# nrf54lc10a_application register map
Vendor: Nordic Semiconductor; Series: nrf54l; File version: 1
CPU: CM33 r0p4, little endian, MPU, FPU, 3 interrupt priority bits, 270 interrupts, 4 SAU regions
Registers are 32-bit, read-write, reset 0x0 unless marked. A register's access mark holds for its fields unless they carry their own. Offsets are from the block's base; [hi:lo] are bit positions; lines under a group give offsets from that group; {n}, {i} and the like mark numbered series; 'fields as' and 'values as' point back to an identical list.

## GLOBAL_RADIO_NS — 2.4 GHz radio 0
Base 0x4008A000
Same registers: GLOBAL_RADIO_S 0x5008A000
0x00 TASKS_TXEN wo — Enable RADIO in TX mode
  [0] TASKS_TXEN
    1=Trigger task
0x04 TASKS_RXEN wo — Enable RADIO in RX mode
  [0] TASKS_RXEN
    1=Trigger task
0x08 TASKS_START wo — Start RADIO
  [0] TASKS_START
    1=Trigger task
0x0C TASKS_STOP wo — Stop RADIO
  [0] TASKS_STOP
    1=Trigger task
0x10 TASKS_DISABLE wo — Disable RADIO
  [0] TASKS_DISABLE
    1=Trigger task
0x14 TASKS_RSSISTART wo — Start the RSSI and take one single sample of the receive signal strength
  [0] TASKS_RSSISTART
    1=Trigger task
0x18 TASKS_BCSTART wo — Start the bit counter
  [0] TASKS_BCSTART
    1=Trigger task
0x1C TASKS_BCSTOP wo — Stop the bit counter
  [0] TASKS_BCSTOP
    1=Trigger task
0x20 TASKS_EDSTART wo — Start the energy detect measurement used in IEEE 802.15.4 mode
  [0] TASKS_EDSTART
    1=Trigger task
0x24 TASKS_EDSTOP wo — Stop the energy detect measurement
  [0] TASKS_EDSTOP
    1=Trigger task
0x28 TASKS_CCASTART wo — Start the clear channel assessment used in IEEE 802.15.4 mode
  [0] TASKS_CCASTART
    1=Trigger task
0x2C TASKS_CCASTOP wo — Stop the clear channel assessment
  [0] TASKS_CCASTOP
    1=Trigger task
0x38 TASKS_AUXDATADMASTART wo — Start DMA transaction of acquisition
  [0] TASKS_AUXDATADMASTART
    1=Trigger task
0x3C TASKS_AUXDATADMASTOP wo — Stop ongoing DMA transaction of acquisition
  [0] TASKS_AUXDATADMASTOP
    1=Trigger task
0x6C TASKS_PLLEN wo — Enable RADIO in PLL mode (standby for either TX or RX)
  [0] TASKS_PLLEN
    1=Trigger task
0xA0 TASKS_CSTONESSTART wo — Start tone processing for channel sounding
  [0] TASKS_CSTONESSTART
    1=Trigger task
0xA4 TASKS_SOFTRESET wo — Reset all public registers, but with these exceptions: DMA registers and EVENT/INTEN/SUBSCRIBE/PUBLISH registers. Only to be used in DISABLED state.
  [0] TASKS_SOFTRESET
    1=Trigger task
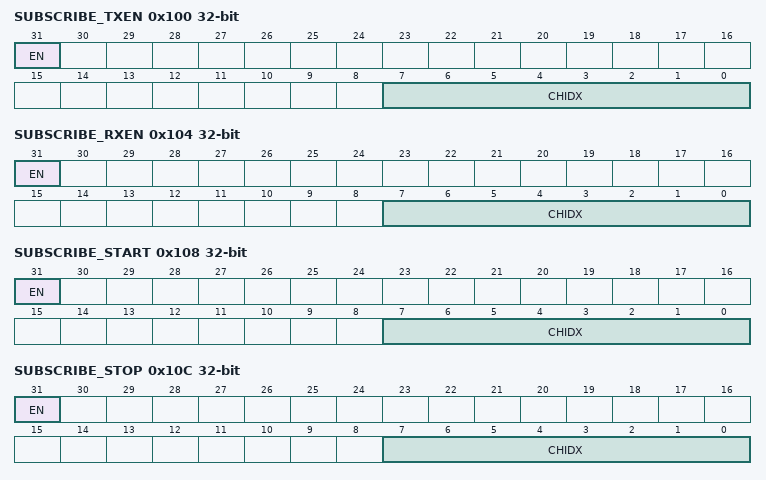
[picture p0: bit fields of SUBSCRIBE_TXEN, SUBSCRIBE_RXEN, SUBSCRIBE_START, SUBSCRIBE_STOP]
0x100 SUBSCRIBE_TXEN — Subscribe configuration for task TXEN
  [31] EN
    0=Disabled (Disable subscription); 1=Enabled (Enable subscription)
  [7:0] CHIDX — DPPI channel that task TXEN will subscribe to
0x104 SUBSCRIBE_RXEN — Subscribe configuration for task RXEN
  [31] EN
    values as SUBSCRIBE_TXEN.EN
  [7:0] CHIDX — DPPI channel that task RXEN will subscribe to
0x108 SUBSCRIBE_START — Subscribe configuration for task START
  [31] EN
    values as SUBSCRIBE_TXEN.EN
  [7:0] CHIDX — DPPI channel that task START will subscribe to
0x10C SUBSCRIBE_STOP — Subscribe configuration for task STOP
  [31] EN
    values as SUBSCRIBE_TXEN.EN
  [7:0] CHIDX — DPPI channel that task STOP will subscribe to
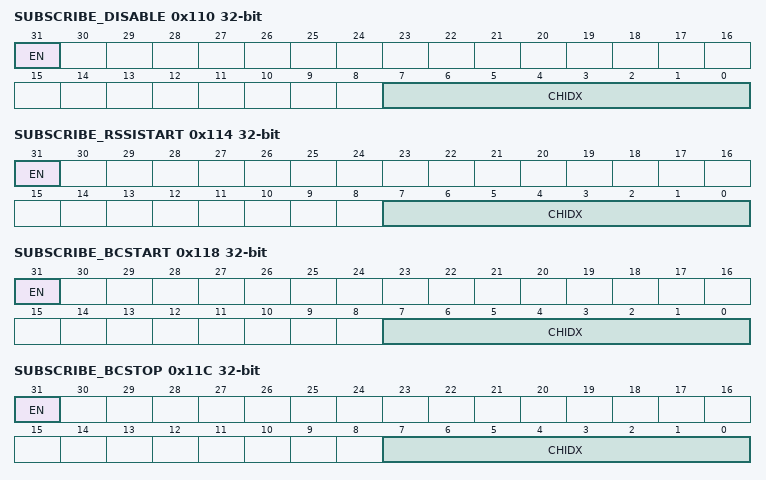
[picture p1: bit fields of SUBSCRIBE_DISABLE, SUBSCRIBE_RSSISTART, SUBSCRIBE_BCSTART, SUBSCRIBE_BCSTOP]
0x110 SUBSCRIBE_DISABLE — Subscribe configuration for task DISABLE
  [31] EN
    values as SUBSCRIBE_TXEN.EN
  [7:0] CHIDX — DPPI channel that task DISABLE will subscribe to
0x114 SUBSCRIBE_RSSISTART — Subscribe configuration for task RSSISTART
  [31] EN
    values as SUBSCRIBE_TXEN.EN
  [7:0] CHIDX — DPPI channel that task RSSISTART will subscribe to
0x118 SUBSCRIBE_BCSTART — Subscribe configuration for task BCSTART
  [31] EN
    values as SUBSCRIBE_TXEN.EN
  [7:0] CHIDX — DPPI channel that task BCSTART will subscribe to
0x11C SUBSCRIBE_BCSTOP — Subscribe configuration for task BCSTOP
  [31] EN
    values as SUBSCRIBE_TXEN.EN
  [7:0] CHIDX — DPPI channel that task BCSTOP will subscribe to
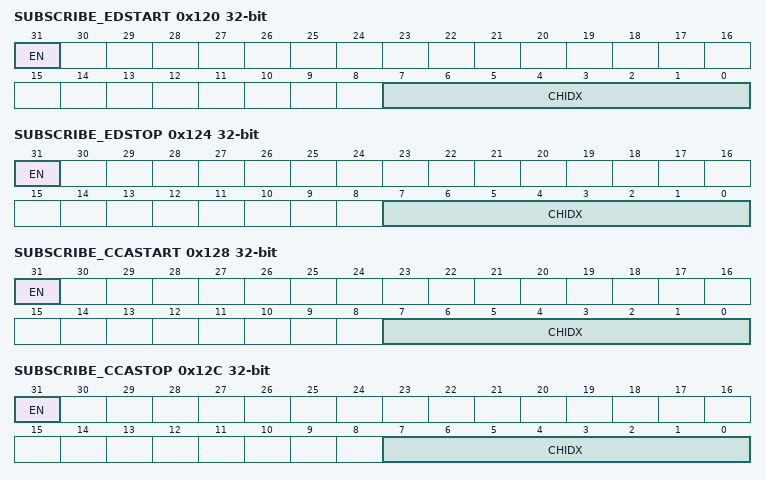
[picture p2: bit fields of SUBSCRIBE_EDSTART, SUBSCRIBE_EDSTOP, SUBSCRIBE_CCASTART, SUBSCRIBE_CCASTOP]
0x120 SUBSCRIBE_EDSTART — Subscribe configuration for task EDSTART
  [31] EN
    values as SUBSCRIBE_TXEN.EN
  [7:0] CHIDX — DPPI channel that task EDSTART will subscribe to
0x124 SUBSCRIBE_EDSTOP — Subscribe configuration for task EDSTOP
  [31] EN
    values as SUBSCRIBE_TXEN.EN
  [7:0] CHIDX — DPPI channel that task EDSTOP will subscribe to
0x128 SUBSCRIBE_CCASTART — Subscribe configuration for task CCASTART
  [31] EN
    values as SUBSCRIBE_TXEN.EN
  [7:0] CHIDX — DPPI channel that task CCASTART will subscribe to
0x12C SUBSCRIBE_CCASTOP — Subscribe configuration for task CCASTOP
  [31] EN
    values as SUBSCRIBE_TXEN.EN
  [7:0] CHIDX — DPPI channel that task CCASTOP will subscribe to
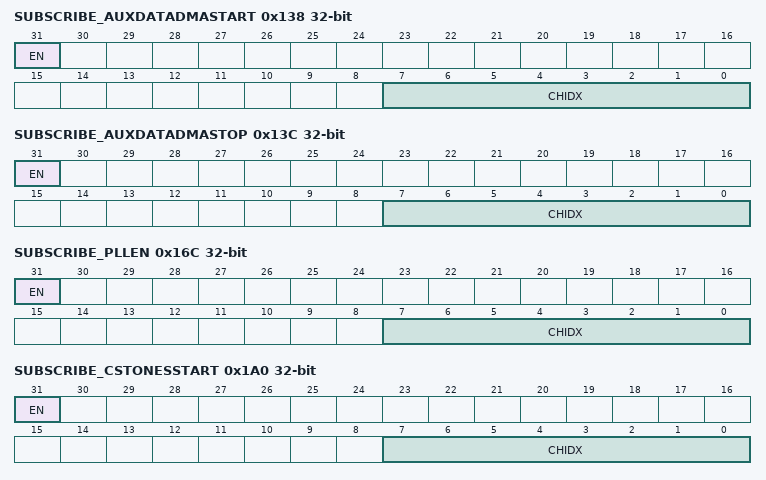
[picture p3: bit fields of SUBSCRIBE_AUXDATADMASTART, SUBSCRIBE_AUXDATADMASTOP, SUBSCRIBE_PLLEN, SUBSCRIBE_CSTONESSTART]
0x138 SUBSCRIBE_AUXDATADMASTART — Subscribe configuration for task AUXDATADMASTART
  [31] EN
    values as SUBSCRIBE_TXEN.EN
  [7:0] CHIDX — DPPI channel that task AUXDATADMASTART will subscribe to
0x13C SUBSCRIBE_AUXDATADMASTOP — Subscribe configuration for task AUXDATADMASTOP
  [31] EN
    values as SUBSCRIBE_TXEN.EN
  [7:0] CHIDX — DPPI channel that task AUXDATADMASTOP will subscribe to
0x16C SUBSCRIBE_PLLEN — Subscribe configuration for task PLLEN
  [31] EN
    values as SUBSCRIBE_TXEN.EN
  [7:0] CHIDX — DPPI channel that task PLLEN will subscribe to
0x1A0 SUBSCRIBE_CSTONESSTART — Subscribe configuration for task CSTONESSTART
  [31] EN
    values as SUBSCRIBE_TXEN.EN
  [7:0] CHIDX — DPPI channel that task CSTONESSTART will subscribe to
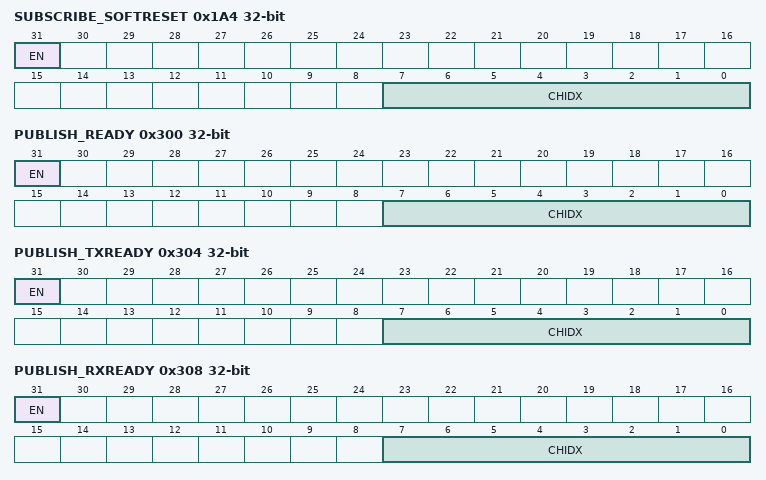
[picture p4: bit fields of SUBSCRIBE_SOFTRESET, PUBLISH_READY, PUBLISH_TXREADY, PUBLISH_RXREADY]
0x1A4 SUBSCRIBE_SOFTRESET — Subscribe configuration for task SOFTRESET
  [31] EN
    values as SUBSCRIBE_TXEN.EN
  [7:0] CHIDX — DPPI channel that task SOFTRESET will subscribe to
0x200 EVENTS_READY — RADIO has ramped up and is ready to be started
  [0] EVENTS_READY
    0=NotGenerated (Event not generated); 1=Generated (Event generated)
0x204 EVENTS_TXREADY — RADIO has ramped up and is ready to be started TX path
  [0] EVENTS_TXREADY
    values as EVENTS_READY.EVENTS_READY
0x208 EVENTS_RXREADY — RADIO has ramped up and is ready to be started RX path
  [0] EVENTS_RXREADY
    values as EVENTS_READY.EVENTS_READY
0x20C EVENTS_ADDRESS — Address sent or received
  [0] EVENTS_ADDRESS
    values as EVENTS_READY.EVENTS_READY
0x210 EVENTS_FRAMESTART — IEEE 802.15.4 length field received
  [0] EVENTS_FRAMESTART
    values as EVENTS_READY.EVENTS_READY
0x214 EVENTS_PAYLOAD — Packet payload sent or received
  [0] EVENTS_PAYLOAD
    values as EVENTS_READY.EVENTS_READY
0x218 EVENTS_END — Memory access for packet data has been completed
  [0] EVENTS_END
    values as EVENTS_READY.EVENTS_READY
0x21C EVENTS_PHYEND — The last bit is sent on air or last bit is received
  [0] EVENTS_PHYEND
    values as EVENTS_READY.EVENTS_READY
0x220 EVENTS_DISABLED — RADIO has been disabled
  [0] EVENTS_DISABLED
    values as EVENTS_READY.EVENTS_READY
0x224 EVENTS_DEVMATCH — A device address match occurred on the last received packet
  [0] EVENTS_DEVMATCH
    values as EVENTS_READY.EVENTS_READY
0x228 EVENTS_DEVMISS — No device address match occurred on the last received packet
  [0] EVENTS_DEVMISS
    values as EVENTS_READY.EVENTS_READY
0x22C EVENTS_CRCOK — Packet received with CRC ok
  [0] EVENTS_CRCOK
    values as EVENTS_READY.EVENTS_READY
0x230 EVENTS_CRCERROR — Packet received with CRC error
  [0] EVENTS_CRCERROR
    values as EVENTS_READY.EVENTS_READY
0x238 EVENTS_BCMATCH — Bit counter reached bit count value
  [0] EVENTS_BCMATCH
    values as EVENTS_READY.EVENTS_READY
0x23C EVENTS_EDEND — Sampling of energy detection complete (a new ED sample is ready for readout from the RADIO.EDSAMPLE register)
  [0] EVENTS_EDEND
    values as EVENTS_READY.EVENTS_READY
0x240 EVENTS_EDSTOPPED — The sampling of energy detection has stopped
  [0] EVENTS_EDSTOPPED
    values as EVENTS_READY.EVENTS_READY
0x244 EVENTS_CCAIDLE — Wireless medium in idle - clear to send
  [0] EVENTS_CCAIDLE
    values as EVENTS_READY.EVENTS_READY
0x248 EVENTS_CCABUSY — Wireless medium busy - do not send
  [0] EVENTS_CCABUSY
    values as EVENTS_READY.EVENTS_READY
0x24C EVENTS_CCASTOPPED — The CCA has stopped
  [0] EVENTS_CCASTOPPED
    values as EVENTS_READY.EVENTS_READY
0x250 EVENTS_RATEBOOST — Ble_LR CI field received, receive mode is changed from Ble_LR125Kbit to Ble_LR500Kbit
  [0] EVENTS_RATEBOOST
    values as EVENTS_READY.EVENTS_READY
0x254 EVENTS_MHRMATCH — MAC header match found
  [0] EVENTS_MHRMATCH
    values as EVENTS_READY.EVENTS_READY
0x258 EVENTS_SYNC — Initial sync detected
  [0] EVENTS_SYNC
    values as EVENTS_READY.EVENTS_READY
0x25C EVENTS_CTEPRESENT — CTEInfo byte is received
  [0] EVENTS_CTEPRESENT
    values as EVENTS_READY.EVENTS_READY
0x2B0 EVENTS_PLLREADY — PLL has settled and RADIO is ready to be enabled in either TX or RX mode
  [0] EVENTS_PLLREADY
    values as EVENTS_READY.EVENTS_READY
0x2BC EVENTS_RXADDRESS — Address received
  [0] EVENTS_RXADDRESS
    values as EVENTS_READY.EVENTS_READY
0x2C0 EVENTS_AUXDATADMAEND — AUXDATA DMA end
  [0] EVENTS_AUXDATADMAEND
    values as EVENTS_READY.EVENTS_READY
0x2C8 EVENTS_CSTONESEND — The channel sounding tone processing is complete
  [0] EVENTS_CSTONESEND
    values as EVENTS_READY.EVENTS_READY
0x300 PUBLISH_READY — Publish configuration for event READY
  [31] EN
    0=Disabled (Disable publishing); 1=Enabled (Enable publishing)
  [7:0] CHIDX — DPPI channel that event READY will publish to
0x304 PUBLISH_TXREADY — Publish configuration for event TXREADY
  [31] EN
    values as PUBLISH_READY.EN
  [7:0] CHIDX — DPPI channel that event TXREADY will publish to
0x308 PUBLISH_RXREADY — Publish configuration for event RXREADY
  [31] EN
    values as PUBLISH_READY.EN
  [7:0] CHIDX — DPPI channel that event RXREADY will publish to
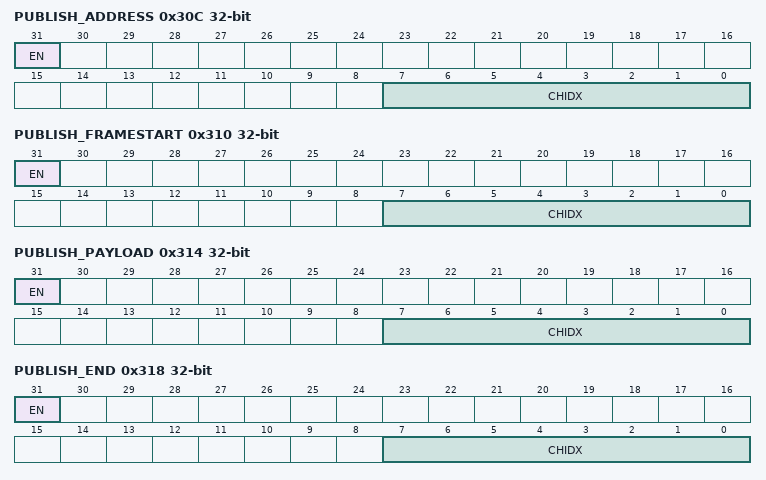
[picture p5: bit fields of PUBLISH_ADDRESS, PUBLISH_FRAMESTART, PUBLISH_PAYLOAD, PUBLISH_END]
0x30C PUBLISH_ADDRESS — Publish configuration for event ADDRESS
  [31] EN
    values as PUBLISH_READY.EN
  [7:0] CHIDX — DPPI channel that event ADDRESS will publish to
0x310 PUBLISH_FRAMESTART — Publish configuration for event FRAMESTART
  [31] EN
    values as PUBLISH_READY.EN
  [7:0] CHIDX — DPPI channel that event FRAMESTART will publish to
0x314 PUBLISH_PAYLOAD — Publish configuration for event PAYLOAD
  [31] EN
    values as PUBLISH_READY.EN
  [7:0] CHIDX — DPPI channel that event PAYLOAD will publish to
0x318 PUBLISH_END — Publish configuration for event END
  [31] EN
    values as PUBLISH_READY.EN
  [7:0] CHIDX — DPPI channel that event END will publish to
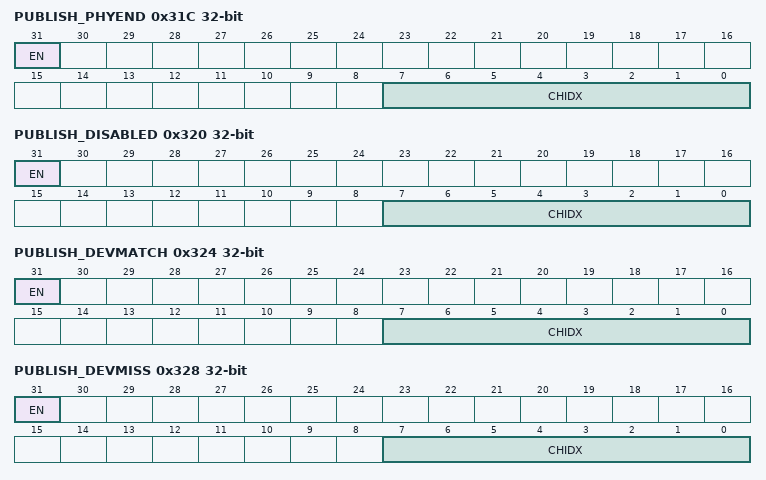
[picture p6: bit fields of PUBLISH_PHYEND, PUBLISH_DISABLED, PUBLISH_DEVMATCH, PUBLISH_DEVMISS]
0x31C PUBLISH_PHYEND — Publish configuration for event PHYEND
  [31] EN
    values as PUBLISH_READY.EN
  [7:0] CHIDX — DPPI channel that event PHYEND will publish to
0x320 PUBLISH_DISABLED — Publish configuration for event DISABLED
  [31] EN
    values as PUBLISH_READY.EN
  [7:0] CHIDX — DPPI channel that event DISABLED will publish to
0x324 PUBLISH_DEVMATCH — Publish configuration for event DEVMATCH
  [31] EN
    values as PUBLISH_READY.EN
  [7:0] CHIDX — DPPI channel that event DEVMATCH will publish to
0x328 PUBLISH_DEVMISS — Publish configuration for event DEVMISS
  [31] EN
    values as PUBLISH_READY.EN
  [7:0] CHIDX — DPPI channel that event DEVMISS will publish to
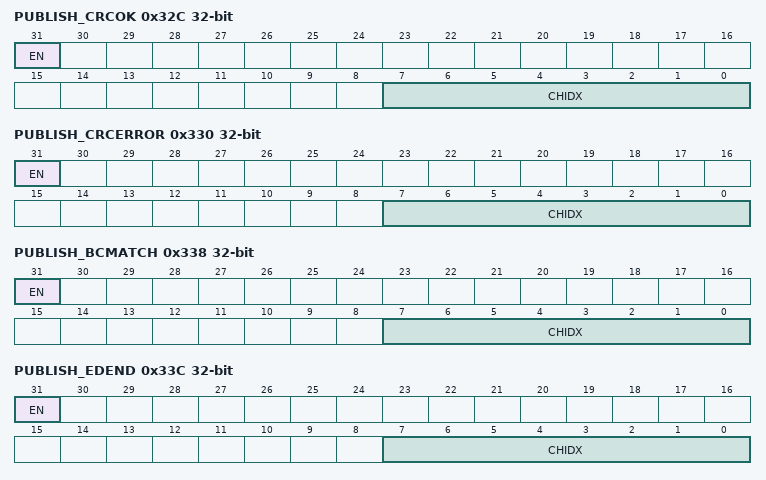
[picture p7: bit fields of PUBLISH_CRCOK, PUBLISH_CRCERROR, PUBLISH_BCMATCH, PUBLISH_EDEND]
0x32C PUBLISH_CRCOK — Publish configuration for event CRCOK
  [31] EN
    values as PUBLISH_READY.EN
  [7:0] CHIDX — DPPI channel that event CRCOK will publish to
0x330 PUBLISH_CRCERROR — Publish configuration for event CRCERROR
  [31] EN
    values as PUBLISH_READY.EN
  [7:0] CHIDX — DPPI channel that event CRCERROR will publish to
0x338 PUBLISH_BCMATCH — Publish configuration for event BCMATCH
  [31] EN
    values as PUBLISH_READY.EN
  [7:0] CHIDX — DPPI channel that event BCMATCH will publish to
0x33C PUBLISH_EDEND — Publish configuration for event EDEND
  [31] EN
    values as PUBLISH_READY.EN
  [7:0] CHIDX — DPPI channel that event EDEND will publish to
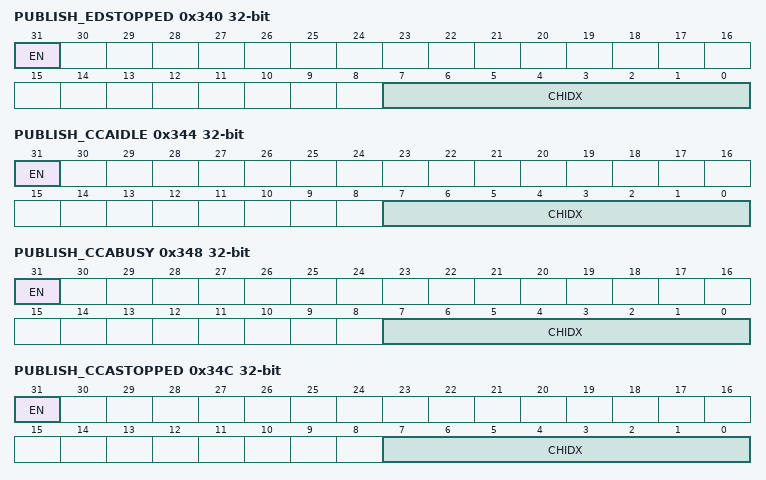
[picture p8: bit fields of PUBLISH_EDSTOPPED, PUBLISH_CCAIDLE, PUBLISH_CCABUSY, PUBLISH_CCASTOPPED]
0x340 PUBLISH_EDSTOPPED — Publish configuration for event EDSTOPPED
  [31] EN
    values as PUBLISH_READY.EN
  [7:0] CHIDX — DPPI channel that event EDSTOPPED will publish to
0x344 PUBLISH_CCAIDLE — Publish configuration for event CCAIDLE
  [31] EN
    values as PUBLISH_READY.EN
  [7:0] CHIDX — DPPI channel that event CCAIDLE will publish to
0x348 PUBLISH_CCABUSY — Publish configuration for event CCABUSY
  [31] EN
    values as PUBLISH_READY.EN
  [7:0] CHIDX — DPPI channel that event CCABUSY will publish to
0x34C PUBLISH_CCASTOPPED — Publish configuration for event CCASTOPPED
  [31] EN
    values as PUBLISH_READY.EN
  [7:0] CHIDX — DPPI channel that event CCASTOPPED will publish to
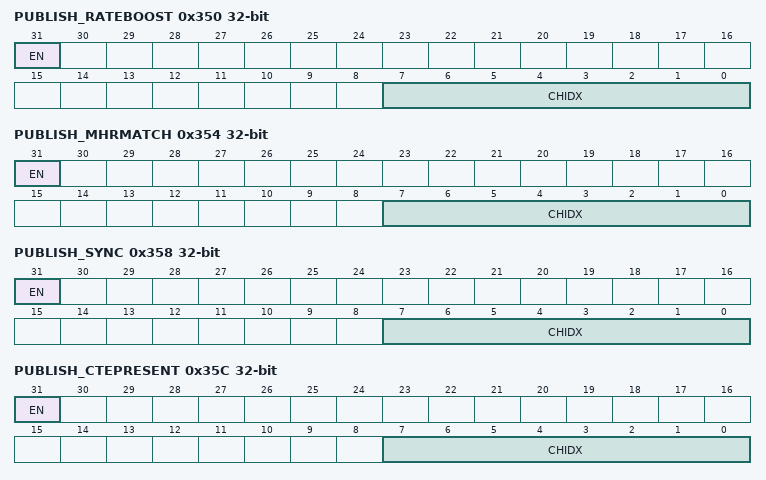
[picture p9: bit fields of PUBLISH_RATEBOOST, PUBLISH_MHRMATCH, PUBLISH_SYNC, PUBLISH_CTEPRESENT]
0x350 PUBLISH_RATEBOOST — Publish configuration for event RATEBOOST
  [31] EN
    values as PUBLISH_READY.EN
  [7:0] CHIDX — DPPI channel that event RATEBOOST will publish to
0x354 PUBLISH_MHRMATCH — Publish configuration for event MHRMATCH
  [31] EN
    values as PUBLISH_READY.EN
  [7:0] CHIDX — DPPI channel that event MHRMATCH will publish to
0x358 PUBLISH_SYNC — Publish configuration for event SYNC
  [31] EN
    values as PUBLISH_READY.EN
  [7:0] CHIDX — DPPI channel that event SYNC will publish to
0x35C PUBLISH_CTEPRESENT — Publish configuration for event CTEPRESENT
  [31] EN
    values as PUBLISH_READY.EN
  [7:0] CHIDX — DPPI channel that event CTEPRESENT will publish to
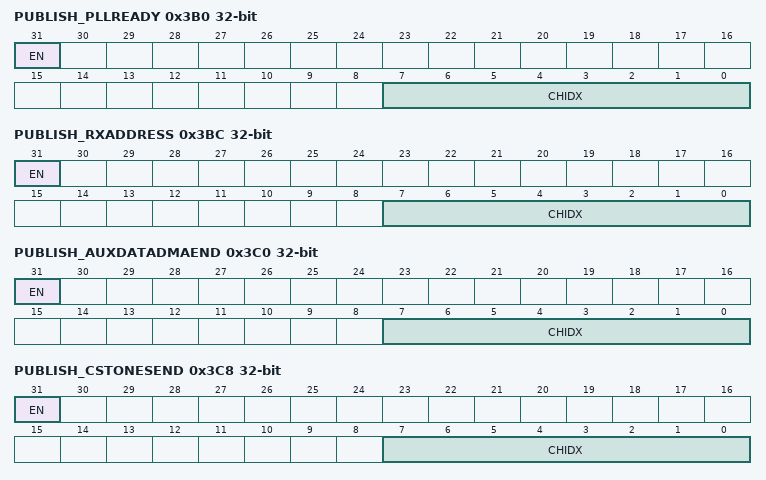
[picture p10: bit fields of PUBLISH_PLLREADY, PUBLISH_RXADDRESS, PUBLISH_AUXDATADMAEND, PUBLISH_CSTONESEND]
0x3B0 PUBLISH_PLLREADY — Publish configuration for event PLLREADY
  [31] EN
    values as PUBLISH_READY.EN
  [7:0] CHIDX — DPPI channel that event PLLREADY will publish to
0x3BC PUBLISH_RXADDRESS — Publish configuration for event RXADDRESS
  [31] EN
    values as PUBLISH_READY.EN
  [7:0] CHIDX — DPPI channel that event RXADDRESS will publish to
0x3C0 PUBLISH_AUXDATADMAEND — Publish configuration for event AUXDATADMAEND
  [31] EN
    values as PUBLISH_READY.EN
  [7:0] CHIDX — DPPI channel that event AUXDATADMAEND will publish to
0x3C8 PUBLISH_CSTONESEND — Publish configuration for event CSTONESEND
  [31] EN
    values as PUBLISH_READY.EN
  [7:0] CHIDX — DPPI channel that event CSTONESEND will publish to
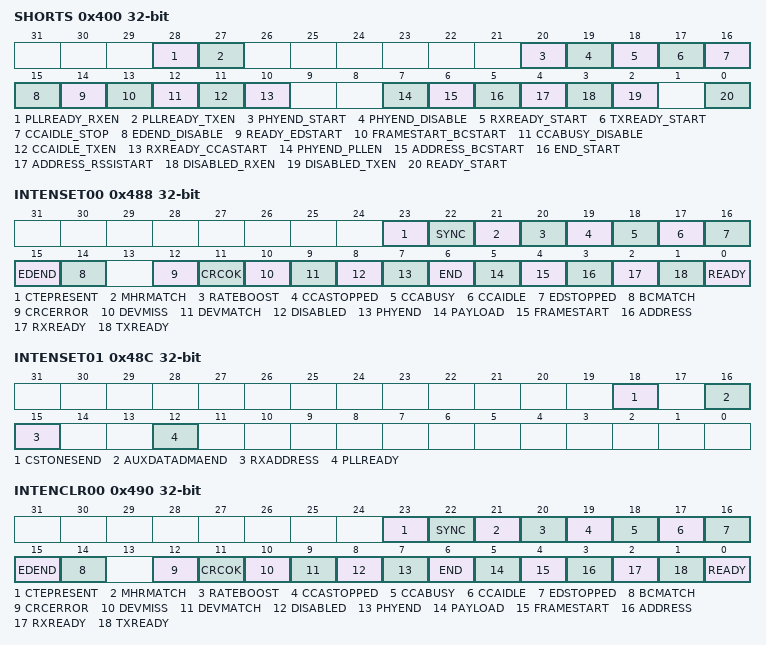
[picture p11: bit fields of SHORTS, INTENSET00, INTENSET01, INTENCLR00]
0x400 SHORTS — Shortcuts between local events and tasks
  [all] fields
    0=Disabled (Disable shortcut); 1=Enabled (Enable shortcut)
  [28] PLLREADY_RXEN — Shortcut between event PLLREADY and task RXEN
  [27] PLLREADY_TXEN — Shortcut between event PLLREADY and task TXEN
  [20] PHYEND_START — Shortcut between event PHYEND and task START
  [19] PHYEND_DISABLE — Shortcut between event PHYEND and task DISABLE
  [18] RXREADY_START — Shortcut between event RXREADY and task START
  [17] TXREADY_START — Shortcut between event TXREADY and task START
  [16] CCAIDLE_STOP — Shortcut between event CCAIDLE and task STOP
  [15] EDEND_DISABLE — Shortcut between event EDEND and task DISABLE
  [14] READY_EDSTART — Shortcut between event READY and task EDSTART
  [13] FRAMESTART_BCSTART — Shortcut between event FRAMESTART and task BCSTART
  [12] CCABUSY_DISABLE — Shortcut between event CCABUSY and task DISABLE
  [11] CCAIDLE_TXEN — Shortcut between event CCAIDLE and task TXEN
  [10] RXREADY_CCASTART — Shortcut between event RXREADY and task CCASTART
  [7] PHYEND_PLLEN — Shortcut between event PHYEND and task PLLEN
  [6] ADDRESS_BCSTART — Shortcut between event ADDRESS and task BCSTART
  [5] END_START — Shortcut between event END and task START
  [4] ADDRESS_RSSISTART — Shortcut between event ADDRESS and task RSSISTART
  [3] DISABLED_RXEN — Shortcut between event DISABLED and task RXEN
  [2] DISABLED_TXEN — Shortcut between event DISABLED and task TXEN
  [0] READY_START — Shortcut between event READY and task START
0x488 INTENSET00 — Enable interrupt
  [all] fields
    on read: 0=Disabled (Read: Disabled); 1=Enabled (Read: Enabled) | on write: 1=Set (Enable)
  [23] CTEPRESENT write-1-sets — Write '1' to enable interrupt for event CTEPRESENT
  [22] SYNC write-1-sets — Write '1' to enable interrupt for event SYNC
  [21] MHRMATCH write-1-sets — Write '1' to enable interrupt for event MHRMATCH
  [20] RATEBOOST write-1-sets — Write '1' to enable interrupt for event RATEBOOST
  [19] CCASTOPPED write-1-sets — Write '1' to enable interrupt for event CCASTOPPED
  [18] CCABUSY write-1-sets — Write '1' to enable interrupt for event CCABUSY
  [17] CCAIDLE write-1-sets — Write '1' to enable interrupt for event CCAIDLE
  [16] EDSTOPPED write-1-sets — Write '1' to enable interrupt for event EDSTOPPED
  [15] EDEND write-1-sets — Write '1' to enable interrupt for event EDEND
  [14] BCMATCH write-1-sets — Write '1' to enable interrupt for event BCMATCH
  [12] CRCERROR write-1-sets — Write '1' to enable interrupt for event CRCERROR
  [11] CRCOK write-1-sets — Write '1' to enable interrupt for event CRCOK
  [10] DEVMISS write-1-sets — Write '1' to enable interrupt for event DEVMISS
  [9] DEVMATCH write-1-sets — Write '1' to enable interrupt for event DEVMATCH
  [8] DISABLED write-1-sets — Write '1' to enable interrupt for event DISABLED
  [7] PHYEND write-1-sets — Write '1' to enable interrupt for event PHYEND
  [6] END write-1-sets — Write '1' to enable interrupt for event END
  [5] PAYLOAD write-1-sets — Write '1' to enable interrupt for event PAYLOAD
  [4] FRAMESTART write-1-sets — Write '1' to enable interrupt for event FRAMESTART
  [3] ADDRESS write-1-sets — Write '1' to enable interrupt for event ADDRESS
  [2] RXREADY write-1-sets — Write '1' to enable interrupt for event RXREADY
  [1] TXREADY write-1-sets — Write '1' to enable interrupt for event TXREADY
  [0] READY write-1-sets — Write '1' to enable interrupt for event READY
0x48C INTENSET01 — Enable interrupt
  [all] fields
    values as the fields of INTENSET00
  [18] CSTONESEND write-1-sets — Write '1' to enable interrupt for event CSTONESEND
  [16] AUXDATADMAEND write-1-sets — Write '1' to enable interrupt for event AUXDATADMAEND
  [15] RXADDRESS write-1-sets — Write '1' to enable interrupt for event RXADDRESS
  [12] PLLREADY write-1-sets — Write '1' to enable interrupt for event PLLREADY
0x490 INTENCLR00 — Disable interrupt
  [all] fields
    on read: 0=Disabled (Read: Disabled); 1=Enabled (Read: Enabled) | on write: 1=Clear (Disable)
  [23] CTEPRESENT write-1-clears — Write '1' to disable interrupt for event CTEPRESENT
  [22] SYNC write-1-clears — Write '1' to disable interrupt for event SYNC
  [21] MHRMATCH write-1-clears — Write '1' to disable interrupt for event MHRMATCH
  [20] RATEBOOST write-1-clears — Write '1' to disable interrupt for event RATEBOOST
  [19] CCASTOPPED write-1-clears — Write '1' to disable interrupt for event CCASTOPPED
  [18] CCABUSY write-1-clears — Write '1' to disable interrupt for event CCABUSY
  [17] CCAIDLE write-1-clears — Write '1' to disable interrupt for event CCAIDLE
  [16] EDSTOPPED write-1-clears — Write '1' to disable interrupt for event EDSTOPPED
  [15] EDEND write-1-clears — Write '1' to disable interrupt for event EDEND
  [14] BCMATCH write-1-clears — Write '1' to disable interrupt for event BCMATCH
  [12] CRCERROR write-1-clears — Write '1' to disable interrupt for event CRCERROR
  [11] CRCOK write-1-clears — Write '1' to disable interrupt for event CRCOK
  [10] DEVMISS write-1-clears — Write '1' to disable interrupt for event DEVMISS
  [9] DEVMATCH write-1-clears — Write '1' to disable interrupt for event DEVMATCH
  [8] DISABLED write-1-clears — Write '1' to disable interrupt for event DISABLED
  [7] PHYEND write-1-clears — Write '1' to disable interrupt for event PHYEND
  [6] END write-1-clears — Write '1' to disable interrupt for event END
  [5] PAYLOAD write-1-clears — Write '1' to disable interrupt for event PAYLOAD
  [4] FRAMESTART write-1-clears — Write '1' to disable interrupt for event FRAMESTART
  [3] ADDRESS write-1-clears — Write '1' to disable interrupt for event ADDRESS
  [2] RXREADY write-1-clears — Write '1' to disable interrupt for event RXREADY
  [1] TXREADY write-1-clears — Write '1' to disable interrupt for event TXREADY
  [0] READY write-1-clears — Write '1' to disable interrupt for event READY
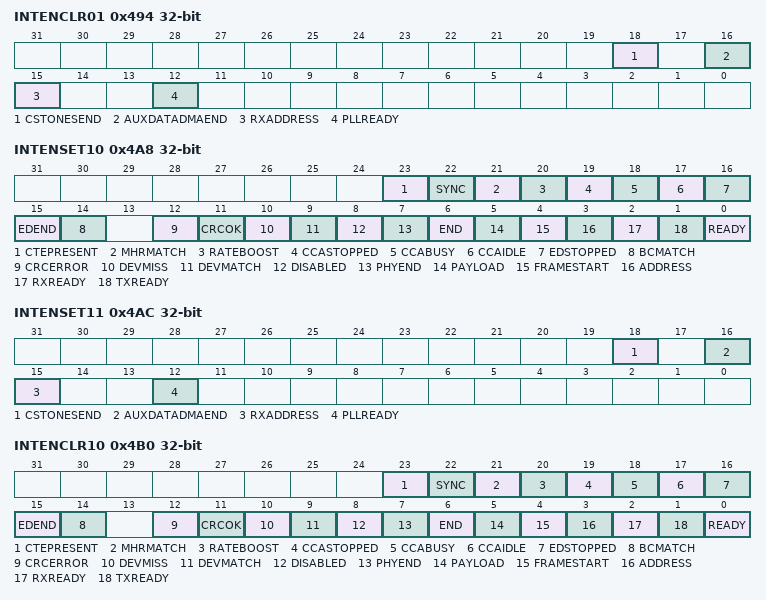
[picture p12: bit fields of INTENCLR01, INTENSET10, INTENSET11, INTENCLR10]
0x494 INTENCLR01 — Disable interrupt
  [all] fields
    values as the fields of INTENCLR00
  [18] CSTONESEND write-1-clears — Write '1' to disable interrupt for event CSTONESEND
  [16] AUXDATADMAEND write-1-clears — Write '1' to disable interrupt for event AUXDATADMAEND
  [15] RXADDRESS write-1-clears — Write '1' to disable interrupt for event RXADDRESS
  [12] PLLREADY write-1-clears — Write '1' to disable interrupt for event PLLREADY
0x4A8 INTENSET10 — Enable interrupt
  fields as INTENSET00
0x4AC INTENSET11 — Enable interrupt
  fields as INTENSET01
0x4B0 INTENCLR10 — Disable interrupt
  fields as INTENCLR00
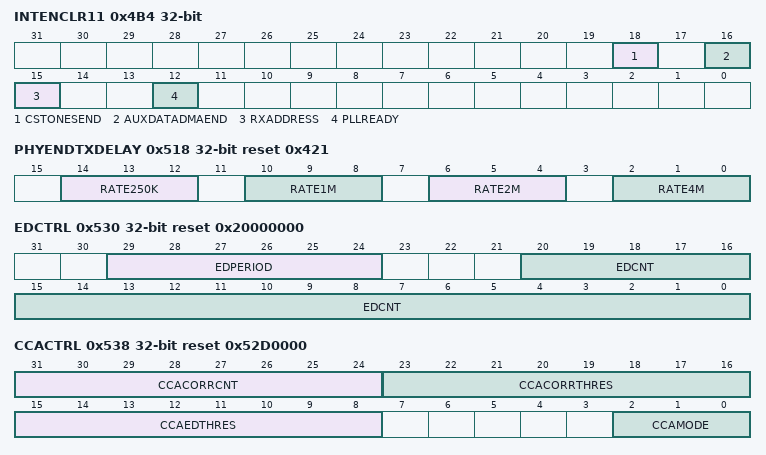
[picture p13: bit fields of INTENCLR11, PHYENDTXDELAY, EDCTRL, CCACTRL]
0x4B4 INTENCLR11 — Disable interrupt
  fields as INTENCLR01
0x500 MODE — Data rate and modulation
  [3:0] MODE — Radio data rate and modulation setting. The radio supports frequency-shift keying (FSK) modulation.
    0=Nrf_1Mbit (1 Mbps Nordic proprietary radio mode); 1=Nrf_2Mbit (2 Mbps Nordic proprietary radio mode); 3=Ble_1Mbit (1 Mbps BLE); 4=Ble_2Mbit (2 Mbps BLE); 5=Ble_LR125Kbit (Long range 125 kbps TX, 125 kbps and 500 kbps RX); 6=Ble_LR500Kbit (Long range 500 kbps TX, 125 kbps and 500 kbps RX); 9=Nrf_4Mbit_0BT6 (4 Mbps Nordic proprietary radio mode (BT=0.6/h=0.5)); 10=Nrf_4Mbit_0BT4 (4 Mbps Nordic proprietary radio mode (BT=0.4/h=0.5)); 15=Ieee802154_250Kbit (IEEE 802.15.4-2006 250 kbps)
0x518 PHYENDTXDELAY reset 0x421 — Configurable delay of PHYEND event for TX
  [14:12] RATE250K — For modes with 250 kbps on-air bit rate, unit is 1/8 bit period (Nrf_250Kbit mode)
  [10:8] RATE1M — For modes with 1 Mbps on-air bit rate, unit is 1/2 bit period (Nrf_1Mbit and Ble_1Mbit modes) Also used for Coded phy (Ble_LR125Kbit and Ble_LR500Kbit modes)
  [6:4] RATE2M — For modes with 2 Mbps on-air bit rate, unit is 1 bit period (Nrf_2Mbit, Ble_2Mbit, and Ieee802154_250Kbit modes)
  [2:0] RATE4M — For modes with 4 Mbps on-air bit rate, unit is 2 bit periods (Nrf_4Mbit0_5 and Nrf_4Mbit0_25 modes)
0x520 STATE ro — Current radio state
  [3:0] STATE
    0=Disabled (RADIO is in the DISABLED state); 1=RxRu (RADIO is in the RXRU state); 2=RxIdle (RADIO is in the RXIDLE state); 3=Rx (RADIO is in the RX state); 4=RxDisable (RADIO is in the RXDISABLE state); 5=Settle (RADIO is in the SETTLE state); 6=Pll (RADIO is in the PLL state); 9=TxRu (RADIO is in the TXRU state); 10=TxIdle (RADIO is in the TXIDLE state); 11=Tx (RADIO is in the TX state); 12=TxDisable (RADIO is in the TXDISABLE state)
0x530 EDCTRL reset 0x20000000 — IEEE 802.15.4 energy detect control
  [29:24] EDPERIOD — IEEE 802.15.4 energy detect period, 4us resolution, no averaging except the IEEE 802.15.4 ED range 128us (32)
    32=Default (Unspecified)
  [20:0] EDCNT — IEEE 802.15.4 energy detect loop count
0x534 EDSAMPLE ro — IEEE 802.15.4 energy detect level
  [7:0] EDLVL
0x538 CCACTRL reset 0x52D0000 — IEEE 802.15.4 clear channel assessment control
  [31:24] CCACORRCNT — Limit for occurances above CCACORRTHRES. When not equal to zero the corrolator based signal detect is enabled.
  [23:16] CCACORRTHRES — CCA correlator busy threshold. Only relevant to CarrierMode, CarrierAndEdMode, and CarrierOrEdMode.
  [15:8] CCAEDTHRES — CCA energy busy threshold. Used in all the CCA modes except CarrierMode.
  [2:0] CCAMODE — CCA mode of operation
    0=EdMode (Energy above threshold); 1=CarrierMode (Carrier seen); 2=CarrierAndEdMode (Energy above threshold AND carrier seen); 3=CarrierOrEdMode (Energy above threshold OR carrier seen); 4=EdModeTest1 (Energy above threshold test mode that will abort when first ED measurement over threshold is seen. No averaging.)
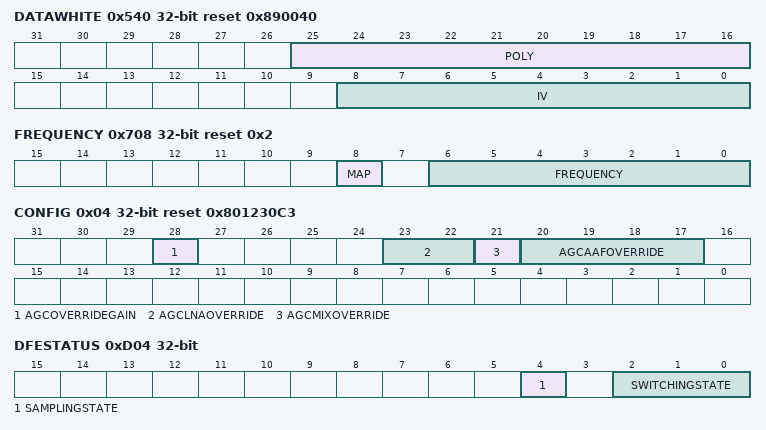
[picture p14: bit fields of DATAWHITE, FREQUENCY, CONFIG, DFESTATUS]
0x540 DATAWHITE reset 0x890040 — Data whitening configuration
  [25:16] POLY — Whitening polynomial
  [8:0] IV — Whitening initial value
0x548 AUXDATA group — Unspecified
  {0x0+4j} CNF[{j}] (j=0..0) — Description collection: AUXDATA configuration
    [4:0] ACQMODE — Acquisition mode
      7=Rtt (Baseband Channel Sounding RTT Data)
{0x550+0x10*i} AUXDATADMA[{i}] (i=0..0) group — Unspecified
  0x00 ENABLE — Description cluster: Enable or disable data acquisition
    [0] ENABLE — Enable or disable data acquisition
      0=Disabled (Data acquisition is disabled); 1=Enabled (Data acquisition is enabled)
  0x04 PTR — Description cluster: DMA pointer
    [31:0] PTR — Data pointer
  0x08 MAXCNT reset 0x40 — Description cluster: Maximum number of 32-bit words to transfer
    [13:0] MAXCNT — Maximum number of 32-bit words to transfer
  0x0C AMOUNT ro — Description cluster: Number of 32-bit words transferred in the last transaction
    [13:0] AMOUNT — Number of 32-bit words transferred in the last transaction
0x704 TIMING reset 0x1
  [0] RU — Ramp-up time
    0=Legacy ramp-up time; 1=Fast ramp-up (default)
0x708 FREQUENCY reset 0x2
  [8] MAP — Channel map selection. 0: Channel map between 2400 MHZ to 2500 MHz, Frequency = 2400 + FREQUENCY (MHz). 1: Channel map between 2360 MHZ to 2460 MHz, Frequency = 2360 + FREQUENCY (MHz).
  [6:0] FREQUENCY — Radio channel frequency. Frequency = 2400 + FREQUENCY (MHz).
0x710 TXPOWER reset 0x13 — Output power
  [10:0] TXPOWER — RADIO output power
    63=MaxdBm (+8 dBm); 63=Pos8dBm (+8 dBm); 57=Pos7dBm (+7 dBm); 51=Pos6dBm (+6 dBm); 45=Pos5dBm (+5 dBm); 40=Pos4dBm (+4 dBm); 35=Pos3dBm (+3 dBm); 31=Pos2dBm (+2 dBm); 27=Pos1dBm (+1 dBm); 24=0dBm; 21=Neg1dBm (-1 dBm); 19=Neg2dBm (-2 dBm); 17=Neg3dBm (-3 dBm); 15=Neg4dBm (-4 dBm); 13=Neg5dBm (-5 dBm); 11=Neg6dBm (-6 dBm); 10=Neg7dBm (-7 dBm); 9=Neg8dBm (-8 dBm); 8=Neg9dBm (-9 dBm); 7=Neg10dBm (-10 dBm); 6=Neg12dBm (-12 dBm); 5=Neg14dBm (-14 dBm); 4=Neg16dBm (-16 dBm); 3=Neg18dBm (-18 dBm); 2=Neg20dBm (-20 dBm); 2=Neg22dBm (-22 dBm); 1=Neg28dBm (-28 dBm); 0x130=Neg40dBm (-40 dBm); 0x110=Neg46dBm (-46 dBm); 0=MindBm (Minimum output power)
0x714 TIFS — Interframe spacing in us
  [9:0] TIFS — Interframe spacing in us. Interframe space is the time interval between two consecutive packets. It is defined as the time, in microseconds, from the end of the last bit of the previous packet to the start of the first bit of the subsequent packet.
0x718 RSSISAMPLE ro reset 0x7F
  [6:0] RSSISAMPLE — RSSI sample result. The value of this register is read as a positive value while the actual received signal strength is a negative value. Actual received signal strength is therefore as follows: received signal strength = -A dBm.
0x7D0 RXGAIN group — Unspecified
  0x04 CONFIG reset 0x801230C3 — Override configuration of receiver gain control loop
    [28] AGCOVERRIDEGAIN — Enable AGC override
      0=NoOverride (AGC takes control over all gains); 1=Override (Manual control of AAF, MIX, and LNA gain settings)
    [23:22] AGCLNAOVERRIDE — Override value for LNA
    [21] AGCMIXOVERRIDE — Override value for MIX
    [20:17] AGCAAFOVERRIDE — Override value for AAF
0x804 FREQFINETUNE — Fine tuning of the RF frequency
  [12:0] FREQFINETUNE — Twos-complement number for fine-tuning the frequency. The step size is 488.28125 Hz, giving a range from -1 MHz to (one step short of) +1 MHz.
0x908 FECONFIG reset 0x10800005 — Config register
  [20] SCALERMODE — Mode for narrow scaling output.
    0=Disabled (Classic log based scaling mode.); 1=Enabled (LUT based scaling mode.)
0xB00 CFO_STAT ro — Carrier freq. offset estimate
  [12] SYNCOK
    0=SyncNotOK (Unspecified); 1=SyncOk (Unspecified)
0xB40 DBCCORR reset 0x1FFFFF90 — Correlator thresholds
  [7:0] TH — Correlation threshold
0xD00 DFEMODE — Whether to use Angle-of-Arrival (AOA) or Angle-of-Departure (AOD)
  [1:0] DFEOPMODE — Direction finding operation mode
    0=Disabled (Direction finding mode disabled); 2=AoD (Direction finding mode set to AoD); 3=AoA (Direction finding mode set to AoA)
0xD04 DFESTATUS ro — DFE status information
  [4] SAMPLINGSTATE — Internal state of sampling state machine
    0=Idle (Sampling state Idle); 1=Sampling state Sampling
  [2:0] SWITCHINGSTATE — Internal state of switching state machine
    0=Idle (Switching state Idle); 1=Offset (Switching state Offset); 2=Guard (Switching state Guard); 3=Ref (Switching state Ref); 4=Switching state Switching; 5=Ending (Switching state Ending)
0xD10 DFECTRL1 reset 0x23282 — Various configuration for Direction finding
  [27:24] AGCBACKOFFGAIN — Gain will be lowered by the specified number of gain steps at the start of CTE
  [23:20] REPEATPATTERN — Repeat every antenna pattern N times.
    0=NoRepeat (Do not repeat (1 time in total))
  [18:16] TSAMPLESPACING — Interval between samples in the SWITCHING period when CTEINLINECTRLEN is 0
    1=4us; 2=2us; 3=1us; 4=500ns (0.5us); 5=250ns (0.25us); 6=125ns (0.125us)
  [15] SAMPLETYPE — Whether to sample I/Q or magnitude/phase
    0=IQ (Complex samples in I and Q); 1=MagPhase (Complex samples as magnitude and phase)
  [14:12] TSAMPLESPACINGREF — Interval between samples in the REFERENCE period
    values as TSAMPLESPACING
  [10:8] TSWITCHSPACING — Interval between every time the antenna is changed in the SWITCHING state
    1=4us; 2=2us; 3=1us
  [7] DFEINEXTENSION — Add CTE extension and do antenna switching/sampling in this extension
    1=CRC (AoA/AoD procedure triggered at end of CRC); 0=Payload (Antenna switching/sampling is done in the packet payload)
  [5:0] NUMBEROF8US — Length of the AoA/AoD procedure in number of 8 us units
0xD14 DFECTRL2 — Start offset for Direction finding
  [27:16] TSAMPLEOFFSET — Signed value offset before starting sampling in number of 16M cycles relative to the beginning of the REFERENCE state - 12 us after switching start
  [12:0] TSWITCHOFFSET — Signed value offset after the end of the CRC before starting switching in number of 16M cycles
0xD28 SWITCHPATTERN — GPIO patterns to be used for each antenna
  [7:0] SWITCHPATTERN — Fill array of GPIO patterns for antenna control
0xD2C CLEARPATTERN wo — Clear the GPIO pattern array for antenna control
  [0] CLEARPATTERN — Clear the GPIO pattern array for antenna control Behaves as a task register, but does not have PPI nor IRQ
0xD30 PSEL group — Unspecified
  {0x0+4j} DFEGPIO[{j}] (j=0..6) reset 0xFFFFFFFF — Description collection: Pin select for DFE pin n
    [31] CONNECT — Connection
      1=Disconnected; 0=Connected
    [8:5] PORT — Port number
    [4:0] PIN — Pin number
0xD50 DFEPACKET group — DFE packet EasyDMA channel
  0x00 PTR — Data pointer
  0x04 MAXCNT reset 0x4000 — Maximum number of bytes to transfer
    [15:0] MAXCNT
  0x08 AMOUNT ro — Number of bytes transferred in the last transaction
    [15:0] AMOUNT
  0x0C CURRENTAMOUNT ro — Number of bytes transferred in the current transaction
    [15:0] AMOUNT — Number of bytes transferred in the current transaction. Continuously updated.
0xE0C CRCSTATUS ro
  [0] CRCSTATUS — CRC status of packet received
    0=CRCError (Packet received with CRC error); 1=CRCOk (Packet received with CRC ok)
0xE10 RXMATCH ro — Received address
  [2:0] RXMATCH
0xE14 RXCRC ro — CRC field of previously received packet
  [23:0] RXCRC
0xE18 DAI ro — Device address match index
  [2:0] DAI
0xE1C PDUSTAT ro — Payload status
  [2:1] CISTAT — Status on what rate packet is received with in Long Range
    0=LR125kbit (Frame is received at 125 kbps); 1=LR500kbit (Frame is received at 500 kbps)
  [0] PDUSTAT — Status on payload length vs. PCNF1.MAXLEN
    0=LessThan (Payload less than PCNF1.MAXLEN); 1=GreaterThan (Payload greater than PCNF1.MAXLEN)
0xE20 PCNF0 — Packet configuration register 0
  [30:29] TERMLEN — Length of TERM field in Long Range operation
  [26] CRCINC — Indicates if LENGTH field contains CRC or not
    0=Exclude (LENGTH does not contain CRC); 1=Include (LENGTH includes CRC)
  [25:24] PLEN — Length of preamble on air. Decision point: TASKS_START task
    0=8-bit preamble; 1=16-bit preamble; 2=32-bit zero preamble - used for IEEE 802.15.4; 3=LongRange (Preamble - used for BLE long range)
  [23:22] CILEN — Length of code indicator - long range
  [21:20] S1INCL — Include or exclude S1 field in RAM
    0=Automatic (Include S1 field in RAM only if S1LEN > 0); 1=Include (Always include S1 field in RAM independent of S1LEN)
  [19:16] S1LEN — Length on air of S1 field in number of bits.
  [8] S0LEN — Length on air of S0 field in number of bytes.
  [3:0] LFLEN — Length on air of LENGTH field in number of bits.
0xE28 PCNF1 — Packet configuration register 1
  [26] WHITEOFFSET — If whitening is enabled S0 can be configured to be excluded from whitening
    0=Include (S0 included in whitening); 1=Exclude (S0 excluded from whitening)
  [25] WHITEEN — Enable or disable packet whitening
    0=Disabled; 1=Enabled
  [24] ENDIAN — On-air endianness of packet, this applies to the S0, LENGTH, S1, and the PAYLOAD fields.
    0=Little (Least significant bit on air first); 1=Big (Most significant bit on air first)
  [18:16] BALEN — Base address length in number of bytes
  [15:8] STATLEN — Static length in number of bytes
  [7:0] MAXLEN — Maximum length of packet payload. If the packet payload is larger than MAXLEN, the radio will truncate the payload to MAXLEN.
0xE2C BASE0 — Base address 0
0xE30 BASE1 — Base address 1
0xE34 PREFIX0 — Prefixes bytes for logical addresses 0-3
  [8n+7:8n] AP{n} (n=0..3) — Address prefix {n}
0xE38 PREFIX1 — Prefixes bytes for logical addresses 4-7
  [8n-25:8n-32] AP{n} (n=4..7) — Address prefix {n}
0xE3C TXADDRESS — Transmit address select
  [2:0] TXADDRESS
0xE40 RXADDRESSES — Receive address select
  [all] fields
    0=Disabled; 1=Enabled
  [n] ADDR{n} (n=0..7) — Enable or disable reception on logical address {n}
0xE44 CRCCNF — CRC configuration
  [10:8] SKIPADDR — Control whether CRC calculation skips the address field. Other fields can also be skipped.
    0=Include (CRC calculation includes address field); 1=Skip (CRC calculation starting at first byte after address field.); 2=Ieee802154 (CRC calculation starting at first byte after length field (as per 802.15.4 standard).); 3=SkipS0 (CRC calculation starting at first byte after S0 field.); 4=SkipS1 (CRC calculation starting at first byte after S1 field.)
  [1:0] LEN — CRC length in number of bytes.
    0=Disabled (CRC length is zero and CRC calculation is disabled); 1=One (CRC length is one byte and CRC calculation is enabled); 2=Two (CRC length is two bytes and CRC calculation is enabled); 3=Three (CRC length is three bytes and CRC calculation is enabled)
0xE48 CRCPOLY — CRC polynomial
  [23:0] CRCPOLY
0xE4C CRCINIT — CRC initial value
  [23:0] CRCINIT
{0xE50+4i} DAB[{i}] (i=0..7) — Description collection: Device address base segment n
  [31:0] DAB — Device address base segment n
{0xE70+4i} DAP[{i}] (i=0..7) — Description collection: Device address prefix n
  [15:0] DAP — Device address prefix n
0xE90 DACNF — Device address match configuration
  [n+8] TXADD{n} (n=0..7) — TxAdd for device address {n}
  [n] ENA{n} (n=0..7) — Enable or disable device address matching using device address {n}
    0=Disabled; 1=Enabled
0xE94 BCC — Bit counter compare
0xEA4 CTESTATUS ro — CTEInfo parsed from received packet
  [7:6] CTETYPE — CTEType parsed from packet
  [5] RFU — RFU parsed from packet
  [4:0] CTETIME — CTETime parsed from packet
0xEB4 MHRMATCHCONF — Search pattern configuration
0xEB8 MHRMATCHMASK — Pattern mask
0xEBC SFD reset 0xA7 — IEEE 802.15.4 start of frame delimiter
  [7:0] SFD — IEEE 802.15.4 start of frame delimiter. Note: the least significant 4 bits of the SFD cannot all be zeros.
0xEC0 CTEINLINECONF reset 0x2800 — Configuration for CTE inline mode
  [31:24] S0MASK — S0 bit mask to set which bit to match
  [23:16] S0CONF — S0 bit pattern to match
  [15:13] CTEINLINERXMODE2US — Spacing between samples for the samples in the SWITCHING period when CTEINLINEMODE is set
    values as DFECTRL1.TSAMPLESPACING
  [12:10] CTEINLINERXMODE1US — Spacing between samples for the samples in the SWITCHING period when CTEINLINEMODE is set
    values as DFECTRL1.TSAMPLESPACING
  [7:6] CTETIMEVALIDRANGE — Max range of CTETime
    0=20 in 8us unit (default) Set to 20 if parsed CTETime is larger han 20; 1=31 in 8us unit; 2=63 in 8us unit
  [4] CTEERRORHANDLING — Sampling/switching if CRC is not OK
    1=Yes (Sampling and antenna switching also when CRC is not OK); 0=No (No sampling and antenna switching when CRC is not OK)
  [3] CTEINFOINS1 — CTEInfo is S1 byte or not
    1=InS1 (CTEInfo is in S1 byte (data PDU)); 0=NotInS1 (CTEInfo is NOT in S1 byte (advertising PDU))
  [0] CTEINLINECTRLEN — Enable parsing of CTEInfo from received packet in BLE modes
    1=Enabled (Parsing of CTEInfo is enabled); 0=Disabled (Parsing of CTEInfo is disabled)
0xED0 PACKETPTR — Packet pointer
  [31:0] PTR — Data pointer
0x1000 CSTONES group — Unspecified
  0x00 MODE reset 0x3 — Selects the mode(s) that are activated on the start signal
    [1] TFM — Enable or disable TFM
      0=Disabled (TFM is disabled); 1=Enabled (TFM is enabled)
    [0] TPM — Enable or disable TPM
      0=Disabled (TPM is disabled); 1=Enabled (TPM is enabled)
  0x04 NUMSAMPLES reset 0xA0 — Number of input samples at 2MHz sample rate
    [7:0] NUMSAMPLES — Maximum value supported is 160
  0x08 NEXTFREQUENCY — The value of FREQUENCY that will be used in the next step
    [6:0] NEXTFREQUENCY — Frequency = 2400 + FREQUENCY (MHz)
  0x14 FAEPEER — FAEPEER (Frequency Actuation Error) of peer if known. Used during Mode 0 steps.
    [7:0] FAEPEER — Units 31.25 ppb.
  0x18 PHASESHIFT — Parameter used in TPM, provided by software
    [15:0] PHASESHIFT — Phase shift used in TPM calculation
  0x1C NUMSAMPLESCOEFF reset 0x199A — Parameter used in TPM, provided by software
    [15:0] NUMSAMPLESCOEFF — Coefficient 2**16/(numSamples/16) in Q1.15 format (Default numsamples value is 160)
  0x20 PCT16 ro — Mean magnitude and mean phase converted to IQ
    [31:16] PCT16Q — Quadrature
    [15:0] PCT16I — Inphase
  0x24 MAGPHASEMEAN ro — Mean magnitude and phase of the signal before it is converted to PCT16
    [31:16] MAG — Mean magnitude
    [15:0] PHASE — Mean phase
  0x28 IQRAWMEAN ro — Mean of IQ values
    [31:16] IQRAWMEANQ — Quadrature
    [15:0] IQRAWMEANI — Inphase
  0x2C MAGSTD ro — Magnitude standard deviation approximation
    [15:0] MAGSTD
  0x34 FFOEST ro — FFO estimate
    [11:0] FFOEST — Units 62.5 ppb. Max range +/-100 ppm plus margin.
  0x38 DOWNSAMPLE — Turn on/off down sample of input IQ-signals
    [1] RATE — Indicating if BLE1M or BLE2M is used
      0=BLE1M (Radio mode BLE1M is used); 1=BLE2m (Deprecated enumerator - Radio mode BLE2M is used); 1=BLE2M (Radio mode BLE2M is used)
    [0] ENABLEFILTER — Turn on/off down sample of input IQ-signals
      0=OFF (Disable filter); 1=ON (Enable filter)
  0x44 FREQOFFSET ro — Frequency offset estimate
    [13:0] FREQOFFSET
0x1050 RTT group — Unspecified
  0x00 CONFIG — RTT Config.
    [16:8] EFSDELAY — Early Frame Sync Delay, i.e., number of cycles to wait for access address to anchor correctly. For Ble_2Mbit, the EFSDELAY value is 64 (2us) and for Ble_1Mbit, it can be 256 (8us).
    [6:3] NUMSEGMENTS — Number of 16bit payload segments available for ToA detection. Allowed values are 0, 2, 4, 6 and 8.
    [2] ROLE — Role as a Initiator or Reflector.
      0=Initiator; 1=Reflector
    [1] ENFULLAA — Enabling/Disable ping over the entire access address.
      0=Disabled (Disable ping over the entire access address, i.e., enable only over the first 16-bit access address); 1=Enabled (Enable ping over the entire access address)
    [0] EN — Enable RTT functionality. Only valid for BLE 1MBPS and 2MBPS mode
      0=Disabled (Disable RTT Block); 1=Enabled (Enable RTT Block)
  0x04 SEGMENT01 — RTT segments 0 and 1
    [31:0] DATA — Data Bits 31 - 0
  0x08 SEGMENT23 — RTT segments 2 and 3
    [31:0] DATA — Data Bits 63 - 32
  0x0C SEGMENT45 — RTT segments 4 and 5
    [31:0] DATA — Data Bits 95 - 64
  0x10 SEGMENT67 — RTT segments 6 and 7
    [31:0] DATA — Data Bits 127 - 96
